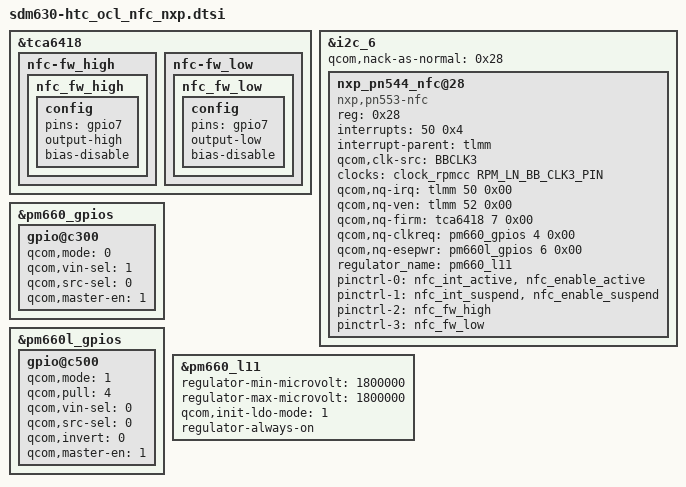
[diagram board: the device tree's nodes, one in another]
&tca6418 {
	nfc-fw_high {
		nfc_fw_high: nfc_fw_high {
			config {
				pins = "gpio7";
				output-high;
				bias-disable;
			};
		};
	};

	nfc-fw_low {
		nfc_fw_low: nfc_fw_low {
			config {
				pins = "gpio7";
				output-low;
				bias-disable;
			};
		};
	};
};

&i2c_6 {
 /delete-node/ nq@28;
};

&i2c_6 {
	qcom,nack-as-normal = <0x28>;
	nxp_pn544_nfc@28 {
	compatible = "nxp,pn553-nfc";
	reg = <0x28>;
	interrupts = <50 0x4>;
	interrupt-parent = <&tlmm>;
	interrupt-names = "nfc_irq";
	clock-names = "ref_clk";
	qcom,clk-src = "BBCLK3";
	clocks = <&clock_rpmcc RPM_LN_BB_CLK3_PIN>;
	qcom,nq-irq = <&tlmm 50 0x00>;
	qcom,nq-ven = <&tlmm 52 0x00>;
	qcom,nq-firm = <&tca6418 7 0x00>;
	qcom,nq-clkreq = <&pm660_gpios 4 0x00>;
	qcom,nq-esepwr = <&pm660l_gpios 6 0x00>;
	regulator_name = "pm660_l11";
	pinctrl-names = "nfc_active", "nfc_suspend", "nfc-fw_high", "nfc-fw_low";
	pinctrl-0 = <&nfc_int_active &nfc_enable_active>;
	pinctrl-1 = <&nfc_int_suspend &nfc_enable_suspend>;
	pinctrl-2 = <&nfc_fw_high>;
	pinctrl-3 = <&nfc_fw_low>;
	};

};

&pm660_gpios {
        /* GPIO 4 (NFC_CLK_REQ) */
        gpio@c300 {
                qcom,mode = <0>;
                qcom,vin-sel = <1>;
                qcom,src-sel = <0>;
                qcom,master-en = <1>;
                status = "okay";
        };
};

&pm660l_gpios {
        gpio@c500 {  /*GPIO_6 NFC ESE_PWR_REQL*/
                qcom,mode = <1>;                /* Output */
                qcom,pull = <4>;                /* Pulldown 10uA */
                qcom,vin-sel = <0>;             /* VIN1 GPIO_LV */
                qcom,src-sel = <0>;             /* GPIO */
                qcom,invert = <0>;              /* Invert 0 INVERT_DISABLE*/
                qcom,master-en = <1>;           /* Enable GPIO */
                status = "ok";
        };
};

&pm660_l11 {  // V_NFC_1V8
        regulator-min-microvolt = <1800000>;
        regulator-max-microvolt = <1800000>;
        qcom,init-ldo-mode = <1>;
        regulator-always-on;
};

